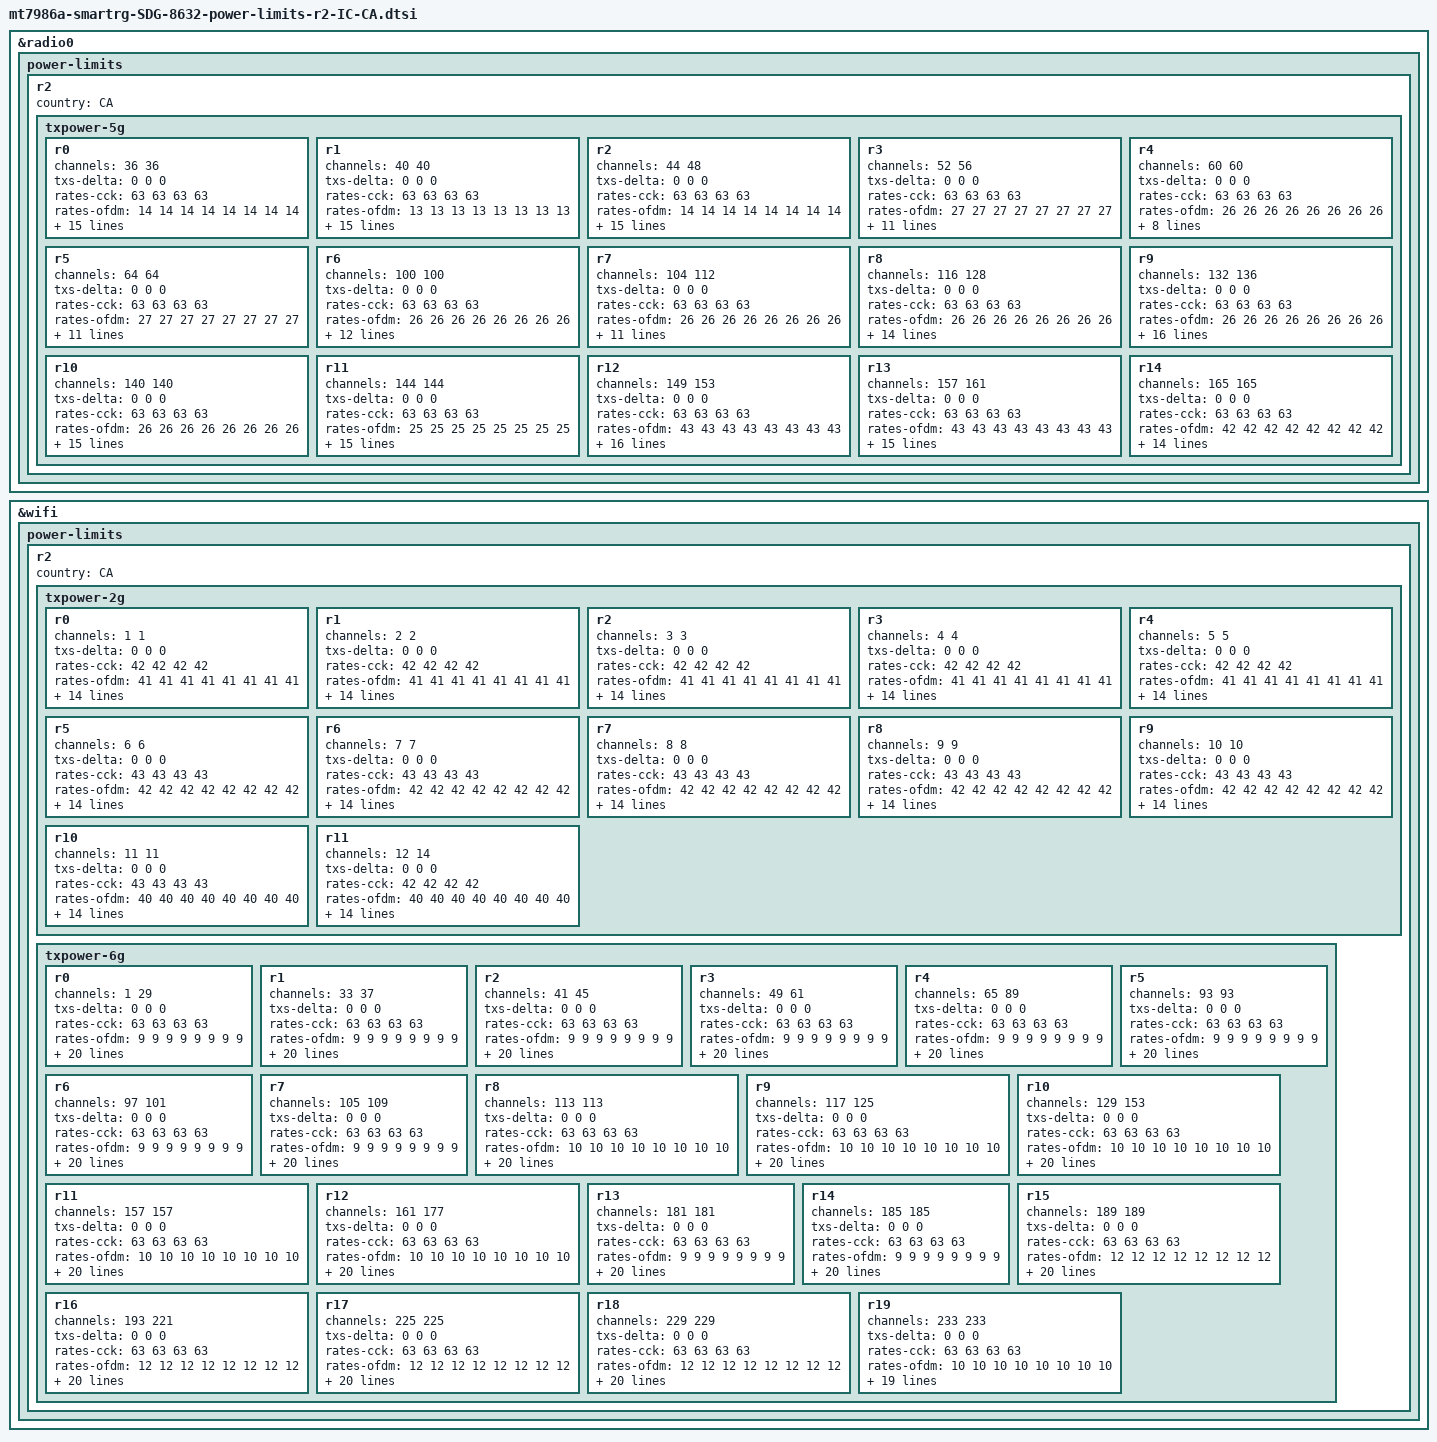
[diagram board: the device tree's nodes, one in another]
// SPDX-License-Identifier: (GPL-2.0 OR MIT)
/*
 * Copyright (C) 2022 SmartRG Inc.
 * Author: Chad Monroe <chad.monroe@smartrg.com>
 */

&radio0 {
	power-limits {
		r2 {
			country = "CA";

			txpower-5g {
				r0 {
					channels = <36 36>;
					txs-delta = <0 0 0>;
					rates-cck = /bits/ 8 <63 63 63 63>;
					rates-ofdm = /bits/ 8 <14 14 14 14 14 14 14 14>;
					rates-mcs =
					/bits/ 8 <1 15 15 15 15 15 15 15 15 15 15>,
					/bits/ 8 <1 19 19 19 19 19 19 19 19 19 19>,
					/bits/ 8 <2 24 24 24 24 24 24 24 24 24 24>;
					rates-ru =
					/bits/ 8 <4 15 15 15 15 15 15 15 15 15 15 15 15>,
					/bits/ 8 <1 19 19 19 19 19 19 19 19 19 19 19 19>,
					/bits/ 8 <2 24 24 24 24 24 24 24 24 24 24 24 24>;
					paths-ofdm = /bits/ 8 <14 14 14 14>;
					paths-ofdm-bf = /bits/ 8 <0 14 14 14>;
					paths-ru =
					/bits/ 8 <4 15 15 15 15 15 15 15 15 15 15>,
					/bits/ 8 <1 19 19 19 19 19 19 19 19 19 19>,
					/bits/ 8 <2 24 24 24 24 24 24 24 24 24 24>;
					paths-ru-bf =
					/bits/ 8 <3 14 14 14 14 14 14 14 14 14 14>,
					/bits/ 8 <1 0 14 14 14 14 14 14 14 14 14>,
					/bits/ 8 <3 0 15 15 15 15 15 15 15 15 15>;
				};
				r1 {
					channels = <40 40>;
					txs-delta = <0 0 0>;
					rates-cck = /bits/ 8 <63 63 63 63>;
					rates-ofdm = /bits/ 8 <13 13 13 13 13 13 13 13>;
					rates-mcs =
					/bits/ 8 <1 15 15 15 15 15 15 15 15 15 15>,
					/bits/ 8 <1 19 19 19 19 19 19 19 19 19 19>,
					/bits/ 8 <2 24 24 24 24 24 24 24 24 24 24>;
					rates-ru =
					/bits/ 8 <4 15 15 15 15 15 15 15 15 15 15 15 15>,
					/bits/ 8 <1 19 19 19 19 19 19 19 19 19 19 19 19>,
					/bits/ 8 <2 24 24 24 24 24 24 24 24 24 24 24 24>;
					paths-ofdm = /bits/ 8 <13 13 13 13>;
					paths-ofdm-bf = /bits/ 8 <0 13 13 13>;
					paths-ru =
					/bits/ 8 <4 15 15 15 15 15 15 15 15 15 15>,
					/bits/ 8 <1 19 19 19 19 19 19 19 19 19 19>,
					/bits/ 8 <2 24 24 24 24 24 24 24 24 24 24>;
					paths-ru-bf =
					/bits/ 8 <3 14 14 14 14 14 14 14 14 14 14>,
					/bits/ 8 <1 0 14 14 14 14 14 14 14 14 14>,
					/bits/ 8 <3 0 15 15 15 15 15 15 15 15 15>;
				};
				r2 {
					channels = <44 48>;
					txs-delta = <0 0 0>;
					rates-cck = /bits/ 8 <63 63 63 63>;
					rates-ofdm = /bits/ 8 <14 14 14 14 14 14 14 14>;
					rates-mcs =
					/bits/ 8 <1 15 15 15 15 15 15 15 15 15 15>,
					/bits/ 8 <1 19 19 19 19 19 19 19 19 19 19>,
					/bits/ 8 <2 24 24 24 24 24 24 24 24 24 24>;
					rates-ru =
					/bits/ 8 <4 15 15 15 15 15 15 15 15 15 15 15 15>,
					/bits/ 8 <1 19 19 19 19 19 19 19 19 19 19 19 19>,
					/bits/ 8 <2 24 24 24 24 24 24 24 24 24 24 24 24>;
					paths-ofdm = /bits/ 8 <14 14 14 14>;
					paths-ofdm-bf = /bits/ 8 <0 14 14 14>;
					paths-ru =
					/bits/ 8 <4 15 15 15 15 15 15 15 15 15 15>,
					/bits/ 8 <1 19 19 19 19 19 19 19 19 19 19>,
					/bits/ 8 <2 24 24 24 24 24 24 24 24 24 24>;
					paths-ru-bf =
					/bits/ 8 <3 14 14 14 14 14 14 14 14 14 14>,
					/bits/ 8 <1 0 14 14 14 14 14 14 14 14 14>,
					/bits/ 8 <3 0 15 15 15 15 15 15 15 15 15>;
				};
				r3 {
					channels = <52 56>;
					txs-delta = <0 0 0>;
					rates-cck = /bits/ 8 <63 63 63 63>;
					rates-ofdm = /bits/ 8 <27 27 27 27 27 27 27 27>;
					rates-mcs =
					/bits/ 8 <1 27 27 27 27 27 27 27 27 27 27>,
					/bits/ 8 <3 26 26 26 26 26 26 26 26 26 26>;
					rates-ru =
					/bits/ 8 <4 27 27 27 27 27 27 27 27 27 27 27 27>,
					/bits/ 8 <3 26 26 26 26 26 26 26 26 26 26 26 26>;
					paths-ofdm = /bits/ 8 <27 27 27 27>;
					paths-ofdm-bf = /bits/ 8 <0 27 27 27>;
					paths-ru =
					/bits/ 8 <4 27 27 27 27 27 27 27 27 27 27>,
					/bits/ 8 <3 26 26 26 26 26 26 26 26 26 26>;
					paths-ru-bf =
					/bits/ 8 <3 15 15 15 15 15 15 15 15 15 15>,
					/bits/ 8 <4 0 15 15 15 15 15 15 15 15 15>;
				};
				r4 {
					channels = <60 60>;
					txs-delta = <0 0 0>;
					rates-cck = /bits/ 8 <63 63 63 63>;
					rates-ofdm = /bits/ 8 <26 26 26 26 26 26 26 26>;
					rates-mcs =
					/bits/ 8 <4 26 26 26 26 26 26 26 26 26 26>;
					rates-ru =
					/bits/ 8 <7 26 26 26 26 26 26 26 26 26 26 26 26>;
					paths-ofdm = /bits/ 8 <26 26 26 26>;
					paths-ofdm-bf = /bits/ 8 <0 26 26 26>;
					paths-ru =
					/bits/ 8 <7 26 26 26 26 26 26 26 26 26 26>;
					paths-ru-bf =
					/bits/ 8 <3 15 15 15 15 15 15 15 15 15 15>,
					/bits/ 8 <4 0 15 15 15 15 15 15 15 15 15>;
				};
				r5 {
					channels = <64 64>;
					txs-delta = <0 0 0>;
					rates-cck = /bits/ 8 <63 63 63 63>;
					rates-ofdm = /bits/ 8 <27 27 27 27 27 27 27 27>;
					rates-mcs =
					/bits/ 8 <1 27 27 27 27 27 27 27 27 27 27>,
					/bits/ 8 <3 26 26 26 26 26 26 26 26 26 26>;
					rates-ru =
					/bits/ 8 <4 27 27 27 27 27 27 27 27 27 27 27 27>,
					/bits/ 8 <3 26 26 26 26 26 26 26 26 26 26 26 26>;
					paths-ofdm = /bits/ 8 <27 27 27 27>;
					paths-ofdm-bf = /bits/ 8 <0 27 27 27>;
					paths-ru =
					/bits/ 8 <4 27 27 27 27 27 27 27 27 27 27>,
					/bits/ 8 <3 26 26 26 26 26 26 26 26 26 26>;
					paths-ru-bf =
					/bits/ 8 <3 15 15 15 15 15 15 15 15 15 15>,
					/bits/ 8 <4 0 15 15 15 15 15 15 15 15 15>;
				};
				r6 {
					channels = <100 100>;
					txs-delta = <0 0 0>;
					rates-cck = /bits/ 8 <63 63 63 63>;
					rates-ofdm = /bits/ 8 <26 26 26 26 26 26 26 26>;
					rates-mcs =
					/bits/ 8 <1 28 28 28 28 28 28 28 28 28 28>,
					/bits/ 8 <3 31 31 31 31 31 31 31 31 31 31>;
					rates-ru =
					/bits/ 8 <4 28 28 28 28 28 28 28 28 28 28 28 28>,
					/bits/ 8 <3 31 31 31 31 31 31 31 31 31 31 31 31>;
					paths-ofdm = /bits/ 8 <26 26 26 26>;
					paths-ofdm-bf = /bits/ 8 <0 26 26 26>;
					paths-ru =
					/bits/ 8 <4 28 28 28 28 28 28 28 28 28 28>,
					/bits/ 8 <3 31 31 31 31 31 31 31 31 31 31>;
					paths-ru-bf =
					/bits/ 8 <3 27 27 27 27 27 27 27 27 27 27>,
					/bits/ 8 <1 0 27 27 27 27 27 27 27 27 27>,
					/bits/ 8 <3 0 28 28 28 28 28 28 28 28 28>;
				};
				r7 {
					channels = <104 112>;
					txs-delta = <0 0 0>;
					rates-cck = /bits/ 8 <63 63 63 63>;
					rates-ofdm = /bits/ 8 <26 26 26 26 26 26 26 26>;
					rates-mcs =
					/bits/ 8 <1 28 28 28 28 28 28 28 28 28 28>,
					/bits/ 8 <3 31 31 31 31 31 31 31 31 31 31>;
					rates-ru =
					/bits/ 8 <4 28 28 28 28 28 28 28 28 28 28 28 28>,
					/bits/ 8 <3 31 31 31 31 31 31 31 31 31 31 31 31>;
					paths-ofdm = /bits/ 8 <26 26 26 26>;
					paths-ofdm-bf = /bits/ 8 <0 26 26 26>;
					paths-ru =
					/bits/ 8 <4 28 28 28 28 28 28 28 28 28 28>,
					/bits/ 8 <3 31 31 31 31 31 31 31 31 31 31>;
					paths-ru-bf =
					/bits/ 8 <3 28 28 28 28 28 28 28 28 28 28>,
					/bits/ 8 <4 0 28 28 28 28 28 28 28 28 28>;
				};
				r8 {
					channels = <116 128>;
					txs-delta = <0 0 0>;
					rates-cck = /bits/ 8 <63 63 63 63>;
					rates-ofdm = /bits/ 8 <26 26 26 26 26 26 26 26>;
					rates-mcs =
					/bits/ 8 <1 28 28 28 28 28 28 28 28 28 28>,
					/bits/ 8 <1 31 31 31 31 31 31 31 31 31 31>,
					/bits/ 8 <2 35 35 35 35 35 35 35 35 35 35>;
					rates-ru =
					/bits/ 8 <4 28 28 28 28 28 28 28 28 28 28 28 28>,
					/bits/ 8 <1 31 31 31 31 31 31 31 31 31 31 31 31>,
					/bits/ 8 <2 35 35 35 35 35 35 35 35 35 35 35 35>;
					paths-ofdm = /bits/ 8 <26 26 26 26>;
					paths-ofdm-bf = /bits/ 8 <0 26 26 26>;
					paths-ru =
					/bits/ 8 <4 28 28 28 28 28 28 28 28 28 28>,
					/bits/ 8 <1 31 31 31 31 31 31 31 31 31 31>,
					/bits/ 8 <2 35 35 35 35 35 35 35 35 35 35>;
					paths-ru-bf =
					/bits/ 8 <3 28 28 28 28 28 28 28 28 28 28>,
					/bits/ 8 <4 0 28 28 28 28 28 28 28 28 28>;
				};
				r9 {
					channels = <132 136>;
					txs-delta = <0 0 0>;
					rates-cck = /bits/ 8 <63 63 63 63>;
					rates-ofdm = /bits/ 8 <26 26 26 26 26 26 26 26>;
					rates-mcs =
					/bits/ 8 <1 28 28 28 28 28 28 28 28 28 28>,
					/bits/ 8 <1 31 31 31 31 31 31 31 31 31 31>,
					/bits/ 8 <2 35 35 35 35 35 35 35 35 35 35>;
					rates-ru =
					/bits/ 8 <4 28 28 28 28 28 28 28 28 28 28 28 28>,
					/bits/ 8 <1 31 31 31 31 31 31 31 31 31 31 31 31>,
					/bits/ 8 <2 35 35 35 35 35 35 35 35 35 35 35 35>;
					paths-ofdm = /bits/ 8 <26 26 26 26>;
					paths-ofdm-bf = /bits/ 8 <0 26 26 26>;
					paths-ru =
					/bits/ 8 <4 28 28 28 28 28 28 28 28 28 28>,
					/bits/ 8 <1 31 31 31 31 31 31 31 31 31 31>,
					/bits/ 8 <2 35 35 35 35 35 35 35 35 35 35>;
					paths-ru-bf =
					/bits/ 8 <3 28 28 28 28 28 28 28 28 28 28>,
					/bits/ 8 <1 0 28 28 28 28 28 28 28 28 28>,
					/bits/ 8 <1 0 29 29 29 29 29 29 29 29 29>,
					/bits/ 8 <2 0 28 28 28 28 28 28 28 28 28>;
				};
				r10 {
					channels = <140 140>;
					txs-delta = <0 0 0>;
					rates-cck = /bits/ 8 <63 63 63 63>;
					rates-ofdm = /bits/ 8 <26 26 26 26 26 26 26 26>;
					rates-mcs =
					/bits/ 8 <1 27 27 27 27 27 27 27 27 27 27>,
					/bits/ 8 <1 32 32 32 32 32 32 32 32 32 32>,
					/bits/ 8 <2 35 35 35 35 35 35 35 35 35 35>;
					rates-ru =
					/bits/ 8 <4 27 27 27 27 27 27 27 27 27 27 27 27>,
					/bits/ 8 <1 32 32 32 32 32 32 32 32 32 32 32 32>,
					/bits/ 8 <2 35 35 35 35 35 35 35 35 35 35 35 35>;
					paths-ofdm = /bits/ 8 <26 26 26 26>;
					paths-ofdm-bf = /bits/ 8 <0 26 26 26>;
					paths-ru =
					/bits/ 8 <4 27 27 27 27 27 27 27 27 27 27>,
					/bits/ 8 <1 32 32 32 32 32 32 32 32 32 32>,
					/bits/ 8 <2 35 35 35 35 35 35 35 35 35 35>;
					paths-ru-bf =
					/bits/ 8 <3 27 27 27 27 27 27 27 27 27 27>,
					/bits/ 8 <1 0 27 27 27 27 27 27 27 27 27>,
					/bits/ 8 <3 0 28 28 28 28 28 28 28 28 28>;
				};
				r11 {
					channels = <144 144>;
					txs-delta = <0 0 0>;
					rates-cck = /bits/ 8 <63 63 63 63>;
					rates-ofdm = /bits/ 8 <25 25 25 25 25 25 25 25>;
					rates-mcs =
					/bits/ 8 <1 26 26 26 26 26 26 26 26 26 26>,
					/bits/ 8 <1 32 32 32 32 32 32 32 32 32 32>,
					/bits/ 8 <2 35 35 35 35 35 35 35 35 35 35>;
					rates-ru =
					/bits/ 8 <4 26 26 26 26 26 26 26 26 26 26 26 26>,
					/bits/ 8 <1 32 32 32 32 32 32 32 32 32 32 32 32>,
					/bits/ 8 <2 35 35 35 35 35 35 35 35 35 35 35 35>;
					paths-ofdm = /bits/ 8 <25 25 25 25>;
					paths-ofdm-bf = /bits/ 8 <0 25 25 25>;
					paths-ru =
					/bits/ 8 <4 26 26 26 26 26 26 26 26 26 26>,
					/bits/ 8 <1 32 32 32 32 32 32 32 32 32 32>,
					/bits/ 8 <2 35 35 35 35 35 35 35 35 35 35>;
					paths-ru-bf =
					/bits/ 8 <3 26 26 26 26 26 26 26 26 26 26>,
					/bits/ 8 <1 0 26 26 26 26 26 26 26 26 26>,
					/bits/ 8 <3 0 28 28 28 28 28 28 28 28 28>;
				};
				r12 {
					channels = <149 153>;
					txs-delta = <0 0 0>;
					rates-cck = /bits/ 8 <63 63 63 63>;
					rates-ofdm = /bits/ 8 <43 43 43 43 43 43 43 43>;
					rates-mcs =
					/bits/ 8 <1 43 43 43 43 43 43 43 43 43 43>,
					/bits/ 8 <1 41 41 41 41 41 41 41 41 41 41>,
					/bits/ 8 <2 34 34 34 34 34 34 34 34 34 34>;
					rates-ru =
					/bits/ 8 <4 43 43 43 43 43 43 43 43 43 43 43 43>,
					/bits/ 8 <1 41 41 41 41 41 41 41 41 41 41 41 41>,
					/bits/ 8 <2 34 34 34 34 34 34 34 34 34 34 34 34>;
					paths-ofdm = /bits/ 8 <43 43 43 43>;
					paths-ofdm-bf = /bits/ 8 <0 43 43 43>;
					paths-ru =
					/bits/ 8 <4 43 43 43 43 43 43 43 43 43 43>,
					/bits/ 8 <1 41 41 41 41 41 41 41 41 41 41>,
					/bits/ 8 <2 34 34 34 34 34 34 34 34 34 34>;
					paths-ru-bf =
					/bits/ 8 <3 40 40 40 40 40 40 40 40 40 40>,
					/bits/ 8 <1 0 40 40 40 40 40 40 40 40 40>,
					/bits/ 8 <1 0 38 38 38 38 38 38 38 38 38>,
					/bits/ 8 <2 0 33 33 33 33 33 33 33 33 33>;
				};
				r13 {
					channels = <157 161>;
					txs-delta = <0 0 0>;
					rates-cck = /bits/ 8 <63 63 63 63>;
					rates-ofdm = /bits/ 8 <43 43 43 43 43 43 43 43>;
					rates-mcs =
					/bits/ 8 <1 42 42 42 42 42 42 42 42 42 42>,
					/bits/ 8 <1 44 44 44 44 44 44 44 44 44 44>,
					/bits/ 8 <2 34 34 34 34 34 34 34 34 34 34>;
					rates-ru =
					/bits/ 8 <4 42 42 42 42 42 42 42 42 42 42 42 42>,
					/bits/ 8 <1 44 44 44 44 44 44 44 44 44 44 44 44>,
					/bits/ 8 <2 34 34 34 34 34 34 34 34 34 34 34 34>;
					paths-ofdm = /bits/ 8 <43 43 43 43>;
					paths-ofdm-bf = /bits/ 8 <0 43 43 43>;
					paths-ru =
					/bits/ 8 <4 42 42 42 42 42 42 42 42 42 42>,
					/bits/ 8 <1 44 44 44 44 44 44 44 44 44 44>,
					/bits/ 8 <2 34 34 34 34 34 34 34 34 34 34>;
					paths-ru-bf =
					/bits/ 8 <3 40 40 40 40 40 40 40 40 40 40>,
					/bits/ 8 <2 0 40 40 40 40 40 40 40 40 40>,
					/bits/ 8 <2 0 33 33 33 33 33 33 33 33 33>;
				};
				r14 {
					channels = <165 165>;
					txs-delta = <0 0 0>;
					rates-cck = /bits/ 8 <63 63 63 63>;
					rates-ofdm = /bits/ 8 <42 42 42 42 42 42 42 42>;
					rates-mcs =
					/bits/ 8 <1 42 42 42 42 42 42 42 42 42 42>,
					/bits/ 8 <3 31 31 31 31 31 31 31 31 31 31>;
					rates-ru =
					/bits/ 8 <4 42 42 42 42 42 42 42 42 42 42 42 42>,
					/bits/ 8 <3 31 31 31 31 31 31 31 31 31 31 31 31>;
					paths-ofdm = /bits/ 8 <42 42 42 42>;
					paths-ofdm-bf = /bits/ 8 <0 42 42 42>;
					paths-ru =
					/bits/ 8 <4 42 42 42 42 42 42 42 42 42 42>,
					/bits/ 8 <1 46 46 46 46 46 46 46 46 46 46>,
					/bits/ 8 <2 31 31 31 31 31 31 31 31 31 31>;
					paths-ru-bf =
					/bits/ 8 <3 40 40 40 40 40 40 40 40 40 40>,
					/bits/ 8 <1 0 40 40 40 40 40 40 40 40 40>,
					/bits/ 8 <1 0 39 39 39 39 39 39 39 39 39>,
					/bits/ 8 <2 0 26 26 26 26 26 26 26 26 26>;
				};
			};
		};
	};
};

&wifi {
	power-limits {
		r2 {
			country = "CA";

			txpower-2g {
				r0 {
					channels = <1 1>;
					txs-delta = <0 0 0>;
					rates-cck = /bits/ 8 <42 42 42 42>;
					rates-ofdm = /bits/ 8 <41 41 41 41 41 41 41 41>;
					rates-mcs =
					/bits/ 8 <1 37 37 37 37 37 37 37 37 37 37>,
					/bits/ 8 <3 30 30 30 30 30 30 30 30 30 30>;
					rates-ru =
					/bits/ 8 <4 37 37 37 37 37 37 37 37 37 37 37 37>,
					/bits/ 8 <3 30 30 30 30 30 30 30 30 30 30 30 30>;
					paths-cck = /bits/ 8 <42 42 42 42>;
					paths-ofdm = /bits/ 8 <41 41 41 41>;
					paths-ofdm-bf = /bits/ 8 <0 27 27 27>;
					paths-ru =
					/bits/ 8 <4 37 37 37 37 37 37 37 37 37 37>,
					/bits/ 8 <1 30 30 30 30 30 30 30 30 30 30>,
					/bits/ 8 <2 37 37 37 37 37 37 37 37 37 37>;
					paths-ru-bf =
					/bits/ 8 <3 27 27 27 27 27 27 27 27 27 27>,
					/bits/ 8 <1 0 27 27 27 27 27 27 27 27 27>,
					/bits/ 8 <3 0 26 26 26 26 26 26 26 26 26>;
				};
				r1 {
					channels = <2 2>;
					txs-delta = <0 0 0>;
					rates-cck = /bits/ 8 <42 42 42 42>;
					rates-ofdm = /bits/ 8 <41 41 41 41 41 41 41 41>;
					rates-mcs =
					/bits/ 8 <1 38 38 38 38 38 38 38 38 38 38>,
					/bits/ 8 <3 30 30 30 30 30 30 30 30 30 30>;
					rates-ru =
					/bits/ 8 <4 38 38 38 38 38 38 38 38 38 38 38 38>,
					/bits/ 8 <3 30 30 30 30 30 30 30 30 30 30 30 30>;
					paths-cck = /bits/ 8 <42 42 42 42>;
					paths-ofdm = /bits/ 8 <41 41 41 41>;
					paths-ofdm-bf = /bits/ 8 <0 29 29 29>;
					paths-ru =
					/bits/ 8 <4 38 38 38 38 38 38 38 38 38 38>,
					/bits/ 8 <1 30 30 30 30 30 30 30 30 30 30>,
					/bits/ 8 <2 38 38 38 38 38 38 38 38 38 38>;
					paths-ru-bf =
					/bits/ 8 <3 29 29 29 29 29 29 29 29 29 29>,
					/bits/ 8 <1 0 29 29 29 29 29 29 29 29 29>,
					/bits/ 8 <3 0 26 26 26 26 26 26 26 26 26>;
				};
				r2 {
					channels = <3 3>;
					txs-delta = <0 0 0>;
					rates-cck = /bits/ 8 <42 42 42 42>;
					rates-ofdm = /bits/ 8 <41 41 41 41 41 41 41 41>;
					rates-mcs =
					/bits/ 8 <1 39 39 39 39 39 39 39 39 39 39>,
					/bits/ 8 <3 30 30 30 30 30 30 30 30 30 30>;
					rates-ru =
					/bits/ 8 <4 39 39 39 39 39 39 39 39 39 39 39 39>,
					/bits/ 8 <3 30 30 30 30 30 30 30 30 30 30 30 30>;
					paths-cck = /bits/ 8 <42 42 42 42>;
					paths-ofdm = /bits/ 8 <41 41 41 41>;
					paths-ofdm-bf = /bits/ 8 <0 35 35 35>;
					paths-ru =
					/bits/ 8 <4 39 39 39 39 39 39 39 39 39 39>,
					/bits/ 8 <1 30 30 30 30 30 30 30 30 30 30>,
					/bits/ 8 <2 39 39 39 39 39 39 39 39 39 39>;
					paths-ru-bf =
					/bits/ 8 <3 35 35 35 35 35 35 35 35 35 35>,
					/bits/ 8 <1 0 35 35 35 35 35 35 35 35 35>,
					/bits/ 8 <3 0 26 26 26 26 26 26 26 26 26>;
				};
				r3 {
					channels = <4 4>;
					txs-delta = <0 0 0>;
					rates-cck = /bits/ 8 <42 42 42 42>;
					rates-ofdm = /bits/ 8 <41 41 41 41 41 41 41 41>;
					rates-mcs =
					/bits/ 8 <1 40 40 40 40 40 40 40 40 40 40>,
					/bits/ 8 <3 32 32 32 32 32 32 32 32 32 32>;
					rates-ru =
					/bits/ 8 <4 40 40 40 40 40 40 40 40 40 40 40 40>,
					/bits/ 8 <3 32 32 32 32 32 32 32 32 32 32 32 32>;
					paths-cck = /bits/ 8 <42 42 42 42>;
					paths-ofdm = /bits/ 8 <41 41 41 41>;
					paths-ofdm-bf = /bits/ 8 <0 37 37 37>;
					paths-ru =
					/bits/ 8 <4 40 40 40 40 40 40 40 40 40 40>,
					/bits/ 8 <1 32 32 32 32 32 32 32 32 32 32>,
					/bits/ 8 <2 40 40 40 40 40 40 40 40 40 40>;
					paths-ru-bf =
					/bits/ 8 <3 37 37 37 37 37 37 37 37 37 37>,
					/bits/ 8 <1 0 37 37 37 37 37 37 37 37 37>,
					/bits/ 8 <3 0 33 33 33 33 33 33 33 33 33>;
				};
				r4 {
					channels = <5 5>;
					txs-delta = <0 0 0>;
					rates-cck = /bits/ 8 <42 42 42 42>;
					rates-ofdm = /bits/ 8 <41 41 41 41 41 41 41 41>;
					rates-mcs =
					/bits/ 8 <1 41 41 41 41 41 41 41 41 41 41>,
					/bits/ 8 <3 34 34 34 34 34 34 34 34 34 34>;
					rates-ru =
					/bits/ 8 <4 41 41 41 41 41 41 41 41 41 41 41 41>,
					/bits/ 8 <3 34 34 34 34 34 34 34 34 34 34 34 34>;
					paths-cck = /bits/ 8 <42 42 42 42>;
					paths-ofdm = /bits/ 8 <41 41 41 41>;
					paths-ofdm-bf = /bits/ 8 <0 39 39 39>;
					paths-ru =
					/bits/ 8 <4 41 41 41 41 41 41 41 41 41 41>,
					/bits/ 8 <1 34 34 34 34 34 34 34 34 34 34>,
					/bits/ 8 <2 41 41 41 41 41 41 41 41 41 41>;
					paths-ru-bf =
					/bits/ 8 <3 39 39 39 39 39 39 39 39 39 39>,
					/bits/ 8 <1 0 39 39 39 39 39 39 39 39 39>,
					/bits/ 8 <3 0 35 35 35 35 35 35 35 35 35>;
				};
				r5 {
					channels = <6 6>;
					txs-delta = <0 0 0>;
					rates-cck = /bits/ 8 <43 43 43 43>;
					rates-ofdm = /bits/ 8 <42 42 42 42 42 42 42 42>;
					rates-mcs =
					/bits/ 8 <1 42 42 42 42 42 42 42 42 42 42>,
					/bits/ 8 <3 37 37 37 37 37 37 37 37 37 37>;
					rates-ru =
					/bits/ 8 <4 42 42 42 42 42 42 42 42 42 42 42 42>,
					/bits/ 8 <3 37 37 37 37 37 37 37 37 37 37 37 37>;
					paths-cck = /bits/ 8 <43 43 43 43>;
					paths-ofdm = /bits/ 8 <42 42 42 42>;
					paths-ofdm-bf = /bits/ 8 <0 40 40 40>;
					paths-ru =
					/bits/ 8 <4 42 42 42 42 42 42 42 42 42 42>,
					/bits/ 8 <1 37 37 37 37 37 37 37 37 37 37>,
					/bits/ 8 <2 42 42 42 42 42 42 42 42 42 42>;
					paths-ru-bf =
					/bits/ 8 <3 40 40 40 40 40 40 40 40 40 40>,
					/bits/ 8 <1 0 40 40 40 40 40 40 40 40 40>,
					/bits/ 8 <3 0 37 37 37 37 37 37 37 37 37>;
				};
				r6 {
					channels = <7 7>;
					txs-delta = <0 0 0>;
					rates-cck = /bits/ 8 <43 43 43 43>;
					rates-ofdm = /bits/ 8 <42 42 42 42 42 42 42 42>;
					rates-mcs =
					/bits/ 8 <1 41 41 41 41 41 41 41 41 41 41>,
					/bits/ 8 <3 33 33 33 33 33 33 33 33 33 33>;
					rates-ru =
					/bits/ 8 <4 41 41 41 41 41 41 41 41 41 41 41 41>,
					/bits/ 8 <3 33 33 33 33 33 33 33 33 33 33 33 33>;
					paths-cck = /bits/ 8 <43 43 43 43>;
					paths-ofdm = /bits/ 8 <42 42 42 42>;
					paths-ofdm-bf = /bits/ 8 <0 39 39 39>;
					paths-ru =
					/bits/ 8 <4 41 41 41 41 41 41 41 41 41 41>,
					/bits/ 8 <1 33 33 33 33 33 33 33 33 33 33>,
					/bits/ 8 <2 41 41 41 41 41 41 41 41 41 41>;
					paths-ru-bf =
					/bits/ 8 <3 39 39 39 39 39 39 39 39 39 39>,
					/bits/ 8 <1 0 39 39 39 39 39 39 39 39 39>,
					/bits/ 8 <3 0 35 35 35 35 35 35 35 35 35>;
				};
				r7 {
					channels = <8 8>;
					txs-delta = <0 0 0>;
					rates-cck = /bits/ 8 <43 43 43 43>;
					rates-ofdm = /bits/ 8 <42 42 42 42 42 42 42 42>;
					rates-mcs =
					/bits/ 8 <1 40 40 40 40 40 40 40 40 40 40>,
					/bits/ 8 <3 31 31 31 31 31 31 31 31 31 31>;
					rates-ru =
					/bits/ 8 <4 40 40 40 40 40 40 40 40 40 40 40 40>,
					/bits/ 8 <3 31 31 31 31 31 31 31 31 31 31 31 31>;
					paths-cck = /bits/ 8 <43 43 43 43>;
					paths-ofdm = /bits/ 8 <42 42 42 42>;
					paths-ofdm-bf = /bits/ 8 <0 37 37 37>;
					paths-ru =
					/bits/ 8 <4 40 40 40 40 40 40 40 40 40 40>,
					/bits/ 8 <1 31 31 31 31 31 31 31 31 31 31>,
					/bits/ 8 <2 40 40 40 40 40 40 40 40 40 40>;
					paths-ru-bf =
					/bits/ 8 <3 37 37 37 37 37 37 37 37 37 37>,
					/bits/ 8 <1 0 37 37 37 37 37 37 37 37 37>,
					/bits/ 8 <3 0 33 33 33 33 33 33 33 33 33>;
				};
				r8 {
					channels = <9 9>;
					txs-delta = <0 0 0>;
					rates-cck = /bits/ 8 <43 43 43 43>;
					rates-ofdm = /bits/ 8 <42 42 42 42 42 42 42 42>;
					rates-mcs =
					/bits/ 8 <1 38 38 38 38 38 38 38 38 38 38>,
					/bits/ 8 <3 29 29 29 29 29 29 29 29 29 29>;
					rates-ru =
					/bits/ 8 <4 38 38 38 38 38 38 38 38 38 38 38 38>,
					/bits/ 8 <3 29 29 29 29 29 29 29 29 29 29 29 29>;
					paths-cck = /bits/ 8 <43 43 43 43>;
					paths-ofdm = /bits/ 8 <42 42 42 42>;
					paths-ofdm-bf = /bits/ 8 <0 35 35 35>;
					paths-ru =
					/bits/ 8 <4 38 38 38 38 38 38 38 38 38 38>,
					/bits/ 8 <1 29 29 29 29 29 29 29 29 29 29>,
					/bits/ 8 <2 38 38 38 38 38 38 38 38 38 38>;
					paths-ru-bf =
					/bits/ 8 <3 35 35 35 35 35 35 35 35 35 35>,
					/bits/ 8 <1 0 35 35 35 35 35 35 35 35 35>,
					/bits/ 8 <3 0 23 23 23 23 23 23 23 23 23>;
				};
				r9 {
					channels = <10 10>;
					txs-delta = <0 0 0>;
					rates-cck = /bits/ 8 <43 43 43 43>;
					rates-ofdm = /bits/ 8 <42 42 42 42 42 42 42 42>;
					rates-mcs =
					/bits/ 8 <1 36 36 36 36 36 36 36 36 36 36>,
					/bits/ 8 <3 27 27 27 27 27 27 27 27 27 27>;
					rates-ru =
					/bits/ 8 <4 36 36 36 36 36 36 36 36 36 36 36 36>,
					/bits/ 8 <3 27 27 27 27 27 27 27 27 27 27 27 27>;
					paths-cck = /bits/ 8 <43 43 43 43>;
					paths-ofdm = /bits/ 8 <42 42 42 42>;
					paths-ofdm-bf = /bits/ 8 <0 27 27 27>;
					paths-ru =
					/bits/ 8 <4 36 36 36 36 36 36 36 36 36 36>,
					/bits/ 8 <1 27 27 27 27 27 27 27 27 27 27>,
					/bits/ 8 <2 36 36 36 36 36 36 36 36 36 36>;
					paths-ru-bf =
					/bits/ 8 <3 27 27 27 27 27 27 27 27 27 27>,
					/bits/ 8 <1 0 27 27 27 27 27 27 27 27 27>,
					/bits/ 8 <3 0 23 23 23 23 23 23 23 23 23>;
				};
				r10 {
					channels = <11 11>;
					txs-delta = <0 0 0>;
					rates-cck = /bits/ 8 <43 43 43 43>;
					rates-ofdm = /bits/ 8 <40 40 40 40 40 40 40 40>;
					rates-mcs =
					/bits/ 8 <1 34 34 34 34 34 34 34 34 34 34>,
					/bits/ 8 <3 25 25 25 25 25 25 25 25 25 25>;
					rates-ru =
					/bits/ 8 <4 34 34 34 34 34 34 34 34 34 34 34 34>,
					/bits/ 8 <3 25 25 25 25 25 25 25 25 25 25 25 25>;
					paths-cck = /bits/ 8 <43 43 43 43>;
					paths-ofdm = /bits/ 8 <40 40 40 40>;
					paths-ofdm-bf = /bits/ 8 <0 25 25 25>;
					paths-ru =
					/bits/ 8 <4 34 34 34 34 34 34 34 34 34 34>,
					/bits/ 8 <1 25 25 25 25 25 25 25 25 25 25>,
					/bits/ 8 <2 34 34 34 34 34 34 34 34 34 34>;
					paths-ru-bf =
					/bits/ 8 <3 25 25 25 25 25 25 25 25 25 25>,
					/bits/ 8 <1 0 25 25 25 25 25 25 25 25 25>,
					/bits/ 8 <3 0 23 23 23 23 23 23 23 23 23>;
				};
				r11 {
					channels = <12 14>;
					txs-delta = <0 0 0>;
					rates-cck = /bits/ 8 <42 42 42 42>;
					rates-ofdm = /bits/ 8 <40 40 40 40 40 40 40 40>;
					rates-mcs =
					/bits/ 8 <1 34 34 34 34 34 34 34 34 34 34>,
					/bits/ 8 <3 25 25 25 25 25 25 25 25 25 25>;
					rates-ru =
					/bits/ 8 <4 34 34 34 34 34 34 34 34 34 34 34 34>,
					/bits/ 8 <3 25 25 25 25 25 25 25 25 25 25 25 25>;
					paths-cck = /bits/ 8 <42 42 42 42>;
					paths-ofdm = /bits/ 8 <40 40 40 40>;
					paths-ofdm-bf = /bits/ 8 <0 25 25 25>;
					paths-ru =
					/bits/ 8 <4 34 34 34 34 34 34 34 34 34 34>,
					/bits/ 8 <1 25 25 25 25 25 25 25 25 25 25>,
					/bits/ 8 <2 34 34 34 34 34 34 34 34 34 34>;
					paths-ru-bf =
					/bits/ 8 <3 25 25 25 25 25 25 25 25 25 25>,
					/bits/ 8 <1 0 25 25 25 25 25 25 25 25 25>,
					/bits/ 8 <3 0 23 23 23 23 23 23 23 23 23>;
				};
			};

			txpower-6g {
				r0 {
					channels = <1 29>;
					txs-delta = <0 0 0>;
					rates-cck = /bits/ 8 <63 63 63 63>;
					rates-ofdm = /bits/ 8 <9 9 9 9 9 9 9 9>;
					rates-mcs =
					/bits/ 8 <1 11 11 11 11 11 11 11 11 11 11>,
					/bits/ 8 <1 17 17 17 17 17 17 17 17 17 17>,
					/bits/ 8 <1 22 22 22 22 22 22 22 22 22 22>,
					/bits/ 8 <1 27 27 27 27 27 27 27 27 27 27>;
					rates-ru =
					/bits/ 8 <4 11 11 11 11 11 11 11 11 11 11 11 11>,
					/bits/ 8 <1 17 17 17 17 17 17 17 17 17 17 17 17>,
					/bits/ 8 <1 22 22 22 22 22 22 22 22 22 22 22 22>,
					/bits/ 8 <1 27 27 27 27 27 27 27 27 27 27 27 27>;
					paths-ofdm = /bits/ 8 <11 11 11 11>;
					paths-ofdm-bf = /bits/ 8 <0 11 11 11>;
					paths-ru =
					/bits/ 8 <4 11 11 11 11 11 11 11 11 11 11>,
					/bits/ 8 <1 17 17 17 17 17 17 17 17 17 17>,
					/bits/ 8 <1 22 22 22 22 22 22 22 22 22 22>,
					/bits/ 8 <1 27 27 27 27 27 27 27 27 27 27>;
					paths-ru-bf =
					/bits/ 8 <3 10 10 10 10 10 10 10 10 10 10>,
					/bits/ 8 <1 0 10 10 10 10 10 10 10 10 10>,
					/bits/ 8 <1 0 16 16 16 16 16 16 16 16 16>,
					/bits/ 8 <1 0 22 22 22 22 22 22 22 22 22>,
					/bits/ 8 <1 0 27 27 27 27 27 27 27 27 27>;
				};
				r1 {
					channels = <33 37>;
					txs-delta = <0 0 0>;
					rates-cck = /bits/ 8 <63 63 63 63>;
					rates-ofdm = /bits/ 8 <9 9 9 9 9 9 9 9>;
					rates-mcs =
					/bits/ 8 <1 11 11 11 11 11 11 11 11 11 11>,
					/bits/ 8 <1 17 17 17 17 17 17 17 17 17 17>,
					/bits/ 8 <1 22 22 22 22 22 22 22 22 22 22>,
					/bits/ 8 <1 28 28 28 28 28 28 28 28 28 28>;
					rates-ru =
					/bits/ 8 <4 11 11 11 11 11 11 11 11 11 11 11 11>,
					/bits/ 8 <1 17 17 17 17 17 17 17 17 17 17 17 17>,
					/bits/ 8 <1 22 22 22 22 22 22 22 22 22 22 22 22>,
					/bits/ 8 <1 28 28 28 28 28 28 28 28 28 28 28 28>;
					paths-ofdm = /bits/ 8 <11 11 11 11>;
					paths-ofdm-bf = /bits/ 8 <0 11 11 11>;
					paths-ru =
					/bits/ 8 <4 11 11 11 11 11 11 11 11 11 11>,
					/bits/ 8 <1 17 17 17 17 17 17 17 17 17 17>,
					/bits/ 8 <1 22 22 22 22 22 22 22 22 22 22>,
					/bits/ 8 <1 28 28 28 28 28 28 28 28 28 28>;
					paths-ru-bf =
					/bits/ 8 <3 10 10 10 10 10 10 10 10 10 10>,
					/bits/ 8 <1 0 10 10 10 10 10 10 10 10 10>,
					/bits/ 8 <1 0 16 16 16 16 16 16 16 16 16>,
					/bits/ 8 <1 0 22 22 22 22 22 22 22 22 22>,
					/bits/ 8 <1 0 27 27 27 27 27 27 27 27 27>;
				};
				r2 {
					channels = <41 45>;
					txs-delta = <0 0 0>;
					rates-cck = /bits/ 8 <63 63 63 63>;
					rates-ofdm = /bits/ 8 <9 9 9 9 9 9 9 9>;
					rates-mcs =
					/bits/ 8 <1 11 11 11 11 11 11 11 11 11 11>,
					/bits/ 8 <1 16 16 16 16 16 16 16 16 16 16>,
					/bits/ 8 <1 22 22 22 22 22 22 22 22 22 22>,
					/bits/ 8 <1 28 28 28 28 28 28 28 28 28 28>;
					rates-ru =
					/bits/ 8 <4 11 11 11 11 11 11 11 11 11 11 11 11>,
					/bits/ 8 <1 16 16 16 16 16 16 16 16 16 16 16 16>,
					/bits/ 8 <1 22 22 22 22 22 22 22 22 22 22 22 22>,
					/bits/ 8 <1 28 28 28 28 28 28 28 28 28 28 28 28>;
					paths-ofdm = /bits/ 8 <11 11 11 11>;
					paths-ofdm-bf = /bits/ 8 <0 11 11 11>;
					paths-ru =
					/bits/ 8 <4 11 11 11 11 11 11 11 11 11 11>,
					/bits/ 8 <1 16 16 16 16 16 16 16 16 16 16>,
					/bits/ 8 <1 22 22 22 22 22 22 22 22 22 22>,
					/bits/ 8 <1 28 28 28 28 28 28 28 28 28 28>;
					paths-ru-bf =
					/bits/ 8 <3 10 10 10 10 10 10 10 10 10 10>,
					/bits/ 8 <1 0 10 10 10 10 10 10 10 10 10>,
					/bits/ 8 <1 0 16 16 16 16 16 16 16 16 16>,
					/bits/ 8 <1 0 22 22 22 22 22 22 22 22 22>,
					/bits/ 8 <1 0 27 27 27 27 27 27 27 27 27>;
				};
				r3 {
					channels = <49 61>;
					txs-delta = <0 0 0>;
					rates-cck = /bits/ 8 <63 63 63 63>;
					rates-ofdm = /bits/ 8 <9 9 9 9 9 9 9 9>;
					rates-mcs =
					/bits/ 8 <1 11 11 11 11 11 11 11 11 11 11>,
					/bits/ 8 <1 16 16 16 16 16 16 16 16 16 16>,
					/bits/ 8 <1 23 23 23 23 23 23 23 23 23 23>,
					/bits/ 8 <1 28 28 28 28 28 28 28 28 28 28>;
					rates-ru =
					/bits/ 8 <4 11 11 11 11 11 11 11 11 11 11 11 11>,
					/bits/ 8 <1 16 16 16 16 16 16 16 16 16 16 16 16>,
					/bits/ 8 <1 23 23 23 23 23 23 23 23 23 23 23 23>,
					/bits/ 8 <1 28 28 28 28 28 28 28 28 28 28 28 28>;
					paths-ofdm = /bits/ 8 <11 11 11 11>;
					paths-ofdm-bf = /bits/ 8 <0 11 11 11>;
					paths-ru =
					/bits/ 8 <4 11 11 11 11 11 11 11 11 11 11>,
					/bits/ 8 <1 16 16 16 16 16 16 16 16 16 16>,
					/bits/ 8 <1 23 23 23 23 23 23 23 23 23 23>,
					/bits/ 8 <1 28 28 28 28 28 28 28 28 28 28>;
					paths-ru-bf =
					/bits/ 8 <3 10 10 10 10 10 10 10 10 10 10>,
					/bits/ 8 <1 0 10 10 10 10 10 10 10 10 10>,
					/bits/ 8 <1 0 16 16 16 16 16 16 16 16 16>,
					/bits/ 8 <1 0 22 22 22 22 22 22 22 22 22>,
					/bits/ 8 <1 0 27 27 27 27 27 27 27 27 27>;
				};
				r4 {
					channels = <65 89>;
					txs-delta = <0 0 0>;
					rates-cck = /bits/ 8 <63 63 63 63>;
					rates-ofdm = /bits/ 8 <9 9 9 9 9 9 9 9>;
					rates-mcs =
					/bits/ 8 <1 11 11 11 11 11 11 11 11 11 11>,
					/bits/ 8 <1 16 16 16 16 16 16 16 16 16 16>,
					/bits/ 8 <1 23 23 23 23 23 23 23 23 23 23>,
					/bits/ 8 <1 27 27 27 27 27 27 27 27 27 27>;
					rates-ru =
					/bits/ 8 <4 11 11 11 11 11 11 11 11 11 11 11 11>,
					/bits/ 8 <1 16 16 16 16 16 16 16 16 16 16 16 16>,
					/bits/ 8 <1 23 23 23 23 23 23 23 23 23 23 23 23>,
					/bits/ 8 <1 27 27 27 27 27 27 27 27 27 27 27 27>;
					paths-ofdm = /bits/ 8 <11 11 11 11>;
					paths-ofdm-bf = /bits/ 8 <0 11 11 11>;
					paths-ru =
					/bits/ 8 <4 11 11 11 11 11 11 11 11 11 11>,
					/bits/ 8 <1 16 16 16 16 16 16 16 16 16 16>,
					/bits/ 8 <1 23 23 23 23 23 23 23 23 23 23>,
					/bits/ 8 <1 27 27 27 27 27 27 27 27 27 27>;
					paths-ru-bf =
					/bits/ 8 <3 10 10 10 10 10 10 10 10 10 10>,
					/bits/ 8 <1 0 10 10 10 10 10 10 10 10 10>,
					/bits/ 8 <1 0 16 16 16 16 16 16 16 16 16>,
					/bits/ 8 <1 0 22 22 22 22 22 22 22 22 22>,
					/bits/ 8 <1 0 27 27 27 27 27 27 27 27 27>;
				};
				r5 {
					channels = <93 93>;
					txs-delta = <0 0 0>;
					rates-cck = /bits/ 8 <63 63 63 63>;
					rates-ofdm = /bits/ 8 <9 9 9 9 9 9 9 9>;
					rates-mcs =
					/bits/ 8 <1 11 11 11 11 11 11 11 11 11 11>,
					/bits/ 8 <1 16 16 16 16 16 16 16 16 16 16>,
					/bits/ 8 <1 23 23 23 23 23 23 23 23 23 23>,
					/bits/ 8 <1 27 27 27 27 27 27 27 27 27 27>;
					rates-ru =
					/bits/ 8 <4 11 11 11 11 11 11 11 11 11 11 11 11>,
					/bits/ 8 <1 16 16 16 16 16 16 16 16 16 16 16 16>,
					/bits/ 8 <1 23 23 23 23 23 23 23 23 23 23 23 23>,
					/bits/ 8 <1 27 27 27 27 27 27 27 27 27 27 27 27>;
					paths-ofdm = /bits/ 8 <11 11 11 11>;
					paths-ofdm-bf = /bits/ 8 <0 11 11 11>;
					paths-ru =
					/bits/ 8 <4 11 11 11 11 11 11 11 11 11 11>,
					/bits/ 8 <1 16 16 16 16 16 16 16 16 16 16>,
					/bits/ 8 <1 23 23 23 23 23 23 23 23 23 23>,
					/bits/ 8 <1 27 27 27 27 27 27 27 27 27 27>;
					paths-ru-bf =
					/bits/ 8 <3 11 11 11 11 11 11 11 11 11 11>,
					/bits/ 8 <1 0 11 11 11 11 11 11 11 11 11>,
					/bits/ 8 <1 0 16 16 16 16 16 16 16 16 16>,
					/bits/ 8 <1 0 22 22 22 22 22 22 22 22 22>,
					/bits/ 8 <1 0 27 27 27 27 27 27 27 27 27>;
				};
				r6 {
					channels = <97 101>;
					txs-delta = <0 0 0>;
					rates-cck = /bits/ 8 <63 63 63 63>;
					rates-ofdm = /bits/ 8 <9 9 9 9 9 9 9 9>;
					rates-mcs =
					/bits/ 8 <1 12 12 12 12 12 12 12 12 12 12>,
					/bits/ 8 <1 17 17 17 17 17 17 17 17 17 17>,
					/bits/ 8 <1 24 24 24 24 24 24 24 24 24 24>,
					/bits/ 8 <1 27 27 27 27 27 27 27 27 27 27>;
					rates-ru =
					/bits/ 8 <4 12 12 12 12 12 12 12 12 12 12 12 12>,
					/bits/ 8 <1 17 17 17 17 17 17 17 17 17 17 17 17>,
					/bits/ 8 <1 24 24 24 24 24 24 24 24 24 24 24 24>,
					/bits/ 8 <1 27 27 27 27 27 27 27 27 27 27 27 27>;
					paths-ofdm = /bits/ 8 <12 12 12 12>;
					paths-ofdm-bf = /bits/ 8 <0 12 12 12>;
					paths-ru =
					/bits/ 8 <4 12 12 12 12 12 12 12 12 12 12>,
					/bits/ 8 <1 17 17 17 17 17 17 17 17 17 17>,
					/bits/ 8 <1 24 24 24 24 24 24 24 24 24 24>,
					/bits/ 8 <1 27 27 27 27 27 27 27 27 27 27>;
					paths-ru-bf =
					/bits/ 8 <3 11 11 11 11 11 11 11 11 11 11>,
					/bits/ 8 <1 0 11 11 11 11 11 11 11 11 11>,
					/bits/ 8 <1 0 16 16 16 16 16 16 16 16 16>,
					/bits/ 8 <1 0 23 23 23 23 23 23 23 23 23>,
					/bits/ 8 <1 0 27 27 27 27 27 27 27 27 27>;
				};
				r7 {
					channels = <105 109>;
					txs-delta = <0 0 0>;
					rates-cck = /bits/ 8 <63 63 63 63>;
					rates-ofdm = /bits/ 8 <9 9 9 9 9 9 9 9>;
					rates-mcs =
					/bits/ 8 <1 11 11 11 11 11 11 11 11 11 11>,
					/bits/ 8 <1 16 16 16 16 16 16 16 16 16 16>,
					/bits/ 8 <1 24 24 24 24 24 24 24 24 24 24>,
					/bits/ 8 <1 27 27 27 27 27 27 27 27 27 27>;
					rates-ru =
					/bits/ 8 <4 11 11 11 11 11 11 11 11 11 11 11 11>,
					/bits/ 8 <1 16 16 16 16 16 16 16 16 16 16 16 16>,
					/bits/ 8 <1 24 24 24 24 24 24 24 24 24 24 24 24>,
					/bits/ 8 <1 27 27 27 27 27 27 27 27 27 27 27 27>;
					paths-ofdm = /bits/ 8 <11 11 11 11>;
					paths-ofdm-bf = /bits/ 8 <0 11 11 11>;
					paths-ru =
					/bits/ 8 <4 11 11 11 11 11 11 11 11 11 11>,
					/bits/ 8 <1 16 16 16 16 16 16 16 16 16 16>,
					/bits/ 8 <1 24 24 24 24 24 24 24 24 24 24>,
					/bits/ 8 <1 27 27 27 27 27 27 27 27 27 27>;
					paths-ru-bf =
					/bits/ 8 <3 11 11 11 11 11 11 11 11 11 11>,
					/bits/ 8 <1 0 11 11 11 11 11 11 11 11 11>,
					/bits/ 8 <1 0 16 16 16 16 16 16 16 16 16>,
					/bits/ 8 <1 0 23 23 23 23 23 23 23 23 23>,
					/bits/ 8 <1 0 27 27 27 27 27 27 27 27 27>;
				};
				r8 {
					channels = <113 113>;
					txs-delta = <0 0 0>;
					rates-cck = /bits/ 8 <63 63 63 63>;
					rates-ofdm = /bits/ 8 <10 10 10 10 10 10 10 10>;
					rates-mcs =
					/bits/ 8 <1 11 11 11 11 11 11 11 11 11 11>,
					/bits/ 8 <1 16 16 16 16 16 16 16 16 16 16>,
					/bits/ 8 <1 22 22 22 22 22 22 22 22 22 22>,
					/bits/ 8 <1 27 27 27 27 27 27 27 27 27 27>;
					rates-ru =
					/bits/ 8 <4 11 11 11 11 11 11 11 11 11 11 11 11>,
					/bits/ 8 <1 16 16 16 16 16 16 16 16 16 16 16 16>,
					/bits/ 8 <1 22 22 22 22 22 22 22 22 22 22 22 22>,
					/bits/ 8 <1 27 27 27 27 27 27 27 27 27 27 27 27>;
					paths-ofdm = /bits/ 8 <11 11 11 11>;
					paths-ofdm-bf = /bits/ 8 <0 11 11 11>;
					paths-ru =
					/bits/ 8 <4 11 11 11 11 11 11 11 11 11 11>,
					/bits/ 8 <1 16 16 16 16 16 16 16 16 16 16>,
					/bits/ 8 <1 22 22 22 22 22 22 22 22 22 22>,
					/bits/ 8 <1 27 27 27 27 27 27 27 27 27 27>;
					paths-ru-bf =
					/bits/ 8 <3 11 11 11 11 11 11 11 11 11 11>,
					/bits/ 8 <1 0 11 11 11 11 11 11 11 11 11>,
					/bits/ 8 <1 0 16 16 16 16 16 16 16 16 16>,
					/bits/ 8 <1 0 22 22 22 22 22 22 22 22 22>,
					/bits/ 8 <1 0 27 27 27 27 27 27 27 27 27>;
				};
				r9 {
					channels = <117 125>;
					txs-delta = <0 0 0>;
					rates-cck = /bits/ 8 <63 63 63 63>;
					rates-ofdm = /bits/ 8 <10 10 10 10 10 10 10 10>;
					rates-mcs =
					/bits/ 8 <1 10 10 10 10 10 10 10 10 10 10>,
					/bits/ 8 <1 16 16 16 16 16 16 16 16 16 16>,
					/bits/ 8 <1 22 22 22 22 22 22 22 22 22 22>,
					/bits/ 8 <1 27 27 27 27 27 27 27 27 27 27>;
					rates-ru =
					/bits/ 8 <4 10 10 10 10 10 10 10 10 10 10 10 10>,
					/bits/ 8 <1 16 16 16 16 16 16 16 16 16 16 16 16>,
					/bits/ 8 <1 22 22 22 22 22 22 22 22 22 22 22 22>,
					/bits/ 8 <1 27 27 27 27 27 27 27 27 27 27 27 27>;
					paths-ofdm = /bits/ 8 <10 10 10 10>;
					paths-ofdm-bf = /bits/ 8 <0 10 10 10>;
					paths-ru =
					/bits/ 8 <4 10 10 10 10 10 10 10 10 10 10>,
					/bits/ 8 <1 16 16 16 16 16 16 16 16 16 16>,
					/bits/ 8 <1 22 22 22 22 22 22 22 22 22 22>,
					/bits/ 8 <1 27 27 27 27 27 27 27 27 27 27>;
					paths-ru-bf =
					/bits/ 8 <3 10 10 10 10 10 10 10 10 10 10>,
					/bits/ 8 <1 0 10 10 10 10 10 10 10 10 10>,
					/bits/ 8 <1 0 16 16 16 16 16 16 16 16 16>,
					/bits/ 8 <1 0 22 22 22 22 22 22 22 22 22>,
					/bits/ 8 <1 0 27 27 27 27 27 27 27 27 27>;
				};
				r10 {
					channels = <129 153>;
					txs-delta = <0 0 0>;
					rates-cck = /bits/ 8 <63 63 63 63>;
					rates-ofdm = /bits/ 8 <10 10 10 10 10 10 10 10>;
					rates-mcs =
					/bits/ 8 <1 10 10 10 10 10 10 10 10 10 10>,
					/bits/ 8 <1 16 16 16 16 16 16 16 16 16 16>,
					/bits/ 8 <1 22 22 22 22 22 22 22 22 22 22>,
					/bits/ 8 <1 28 28 28 28 28 28 28 28 28 28>;
					rates-ru =
					/bits/ 8 <4 10 10 10 10 10 10 10 10 10 10 10 10>,
					/bits/ 8 <1 16 16 16 16 16 16 16 16 16 16 16 16>,
					/bits/ 8 <1 22 22 22 22 22 22 22 22 22 22 22 22>,
					/bits/ 8 <1 28 28 28 28 28 28 28 28 28 28 28 28>;
					paths-ofdm = /bits/ 8 <10 10 10 10>;
					paths-ofdm-bf = /bits/ 8 <0 10 10 10>;
					paths-ru =
					/bits/ 8 <4 10 10 10 10 10 10 10 10 10 10>,
					/bits/ 8 <1 16 16 16 16 16 16 16 16 16 16>,
					/bits/ 8 <1 22 22 22 22 22 22 22 22 22 22>,
					/bits/ 8 <1 28 28 28 28 28 28 28 28 28 28>;
					paths-ru-bf =
					/bits/ 8 <3 10 10 10 10 10 10 10 10 10 10>,
					/bits/ 8 <1 0 10 10 10 10 10 10 10 10 10>,
					/bits/ 8 <1 0 16 16 16 16 16 16 16 16 16>,
					/bits/ 8 <1 0 22 22 22 22 22 22 22 22 22>,
					/bits/ 8 <1 0 27 27 27 27 27 27 27 27 27>;
				};
				r11 {
					channels = <157 157>;
					txs-delta = <0 0 0>;
					rates-cck = /bits/ 8 <63 63 63 63>;
					rates-ofdm = /bits/ 8 <10 10 10 10 10 10 10 10>;
					rates-mcs =
					/bits/ 8 <1 11 11 11 11 11 11 11 11 11 11>,
					/bits/ 8 <1 16 16 16 16 16 16 16 16 16 16>,
					/bits/ 8 <1 22 22 22 22 22 22 22 22 22 22>,
					/bits/ 8 <1 28 28 28 28 28 28 28 28 28 28>;
					rates-ru =
					/bits/ 8 <4 11 11 11 11 11 11 11 11 11 11 11 11>,
					/bits/ 8 <1 16 16 16 16 16 16 16 16 16 16 16 16>,
					/bits/ 8 <1 22 22 22 22 22 22 22 22 22 22 22 22>,
					/bits/ 8 <1 28 28 28 28 28 28 28 28 28 28 28 28>;
					paths-ofdm = /bits/ 8 <11 11 11 11>;
					paths-ofdm-bf = /bits/ 8 <0 11 11 11>;
					paths-ru =
					/bits/ 8 <4 11 11 11 11 11 11 11 11 11 11>,
					/bits/ 8 <1 16 16 16 16 16 16 16 16 16 16>,
					/bits/ 8 <1 22 22 22 22 22 22 22 22 22 22>,
					/bits/ 8 <1 28 28 28 28 28 28 28 28 28 28>;
					paths-ru-bf =
					/bits/ 8 <3 10 10 10 10 10 10 10 10 10 10>,
					/bits/ 8 <1 0 10 10 10 10 10 10 10 10 10>,
					/bits/ 8 <1 0 16 16 16 16 16 16 16 16 16>,
					/bits/ 8 <1 0 22 22 22 22 22 22 22 22 22>,
					/bits/ 8 <1 0 27 27 27 27 27 27 27 27 27>;
				};
				r12 {
					channels = <161 177>;
					txs-delta = <0 0 0>;
					rates-cck = /bits/ 8 <63 63 63 63>;
					rates-ofdm = /bits/ 8 <10 10 10 10 10 10 10 10>;
					rates-mcs =
					/bits/ 8 <1 11 11 11 11 11 11 11 11 11 11>,
					/bits/ 8 <1 16 16 16 16 16 16 16 16 16 16>,
					/bits/ 8 <1 23 23 23 23 23 23 23 23 23 23>,
					/bits/ 8 <1 27 27 27 27 27 27 27 27 27 27>;
					rates-ru =
					/bits/ 8 <4 11 11 11 11 11 11 11 11 11 11 11 11>,
					/bits/ 8 <1 16 16 16 16 16 16 16 16 16 16 16 16>,
					/bits/ 8 <1 23 23 23 23 23 23 23 23 23 23 23 23>,
					/bits/ 8 <1 27 27 27 27 27 27 27 27 27 27 27 27>;
					paths-ofdm = /bits/ 8 <11 11 11 11>;
					paths-ofdm-bf = /bits/ 8 <0 11 11 11>;
					paths-ru =
					/bits/ 8 <4 11 11 11 11 11 11 11 11 11 11>,
					/bits/ 8 <1 16 16 16 16 16 16 16 16 16 16>,
					/bits/ 8 <1 23 23 23 23 23 23 23 23 23 23>,
					/bits/ 8 <1 27 27 27 27 27 27 27 27 27 27>;
					paths-ru-bf =
					/bits/ 8 <3 10 10 10 10 10 10 10 10 10 10>,
					/bits/ 8 <1 0 10 10 10 10 10 10 10 10 10>,
					/bits/ 8 <1 0 16 16 16 16 16 16 16 16 16>,
					/bits/ 8 <1 0 22 22 22 22 22 22 22 22 22>,
					/bits/ 8 <1 0 27 27 27 27 27 27 27 27 27>;
				};
				r13 {
					channels = <181 181>;
					txs-delta = <0 0 0>;
					rates-cck = /bits/ 8 <63 63 63 63>;
					rates-ofdm = /bits/ 8 <9 9 9 9 9 9 9 9>;
					rates-mcs =
					/bits/ 8 <1 11 11 11 11 11 11 11 11 11 11>,
					/bits/ 8 <1 16 16 16 16 16 16 16 16 16 16>,
					/bits/ 8 <1 23 23 23 23 23 23 23 23 23 23>,
					/bits/ 8 <1 27 27 27 27 27 27 27 27 27 27>;
					rates-ru =
					/bits/ 8 <4 11 11 11 11 11 11 11 11 11 11 11 11>,
					/bits/ 8 <1 16 16 16 16 16 16 16 16 16 16 16 16>,
					/bits/ 8 <1 23 23 23 23 23 23 23 23 23 23 23 23>,
					/bits/ 8 <1 27 27 27 27 27 27 27 27 27 27 27 27>;
					paths-ofdm = /bits/ 8 <11 11 11 11>;
					paths-ofdm-bf = /bits/ 8 <0 11 11 11>;
					paths-ru =
					/bits/ 8 <4 11 11 11 11 11 11 11 11 11 11>,
					/bits/ 8 <1 16 16 16 16 16 16 16 16 16 16>,
					/bits/ 8 <1 23 23 23 23 23 23 23 23 23 23>,
					/bits/ 8 <1 27 27 27 27 27 27 27 27 27 27>;
					paths-ru-bf =
					/bits/ 8 <3 10 10 10 10 10 10 10 10 10 10>,
					/bits/ 8 <1 0 10 10 10 10 10 10 10 10 10>,
					/bits/ 8 <1 0 16 16 16 16 16 16 16 16 16>,
					/bits/ 8 <1 0 22 22 22 22 22 22 22 22 22>,
					/bits/ 8 <1 0 27 27 27 27 27 27 27 27 27>;
				};
				r14 {
					channels = <185 185>;
					txs-delta = <0 0 0>;
					rates-cck = /bits/ 8 <63 63 63 63>;
					rates-ofdm = /bits/ 8 <9 9 9 9 9 9 9 9>;
					rates-mcs =
					/bits/ 8 <1 11 11 11 11 11 11 11 11 11 11>,
					/bits/ 8 <1 16 16 16 16 16 16 16 16 16 16>,
					/bits/ 8 <1 23 23 23 23 23 23 23 23 23 23>,
					/bits/ 8 <1 27 27 27 27 27 27 27 27 27 27>;
					rates-ru =
					/bits/ 8 <4 11 11 11 11 11 11 11 11 11 11 11 11>,
					/bits/ 8 <1 16 16 16 16 16 16 16 16 16 16 16 16>,
					/bits/ 8 <1 23 23 23 23 23 23 23 23 23 23 23 23>,
					/bits/ 8 <1 27 27 27 27 27 27 27 27 27 27 27 27>;
					paths-ofdm = /bits/ 8 <11 11 11 11>;
					paths-ofdm-bf = /bits/ 8 <0 11 11 11>;
					paths-ru =
					/bits/ 8 <4 11 11 11 11 11 11 11 11 11 11>,
					/bits/ 8 <1 16 16 16 16 16 16 16 16 16 16>,
					/bits/ 8 <1 23 23 23 23 23 23 23 23 23 23>,
					/bits/ 8 <1 27 27 27 27 27 27 27 27 27 27>;
					paths-ru-bf =
					/bits/ 8 <3 11 11 11 11 11 11 11 11 11 11>,
					/bits/ 8 <1 0 11 11 11 11 11 11 11 11 11>,
					/bits/ 8 <1 0 15 15 15 15 15 15 15 15 15>,
					/bits/ 8 <1 0 22 22 22 22 22 22 22 22 22>,
					/bits/ 8 <1 0 27 27 27 27 27 27 27 27 27>;
				};
				r15 {
					channels = <189 189>;
					txs-delta = <0 0 0>;
					rates-cck = /bits/ 8 <63 63 63 63>;
					rates-ofdm = /bits/ 8 <12 12 12 12 12 12 12 12>;
					rates-mcs =
					/bits/ 8 <1 13 13 13 13 13 13 13 13 13 13>,
					/bits/ 8 <1 16 16 16 16 16 16 16 16 16 16>,
					/bits/ 8 <1 23 23 23 23 23 23 23 23 23 23>,
					/bits/ 8 <1 27 27 27 27 27 27 27 27 27 27>;
					rates-ru =
					/bits/ 8 <4 13 13 13 13 13 13 13 13 13 13 13 13>,
					/bits/ 8 <1 16 16 16 16 16 16 16 16 16 16 16 16>,
					/bits/ 8 <1 23 23 23 23 23 23 23 23 23 23 23 23>,
					/bits/ 8 <1 27 27 27 27 27 27 27 27 27 27 27 27>;
					paths-ofdm = /bits/ 8 <13 13 13 13>;
					paths-ofdm-bf = /bits/ 8 <0 13 13 13>;
					paths-ru =
					/bits/ 8 <4 13 13 13 13 13 13 13 13 13 13>,
					/bits/ 8 <1 16 16 16 16 16 16 16 16 16 16>,
					/bits/ 8 <1 23 23 23 23 23 23 23 23 23 23>,
					/bits/ 8 <1 27 27 27 27 27 27 27 27 27 27>;
					paths-ru-bf =
					/bits/ 8 <3 13 13 13 13 13 13 13 13 13 13>,
					/bits/ 8 <1 0 13 13 13 13 13 13 13 13 13>,
					/bits/ 8 <1 0 15 15 15 15 15 15 15 15 15>,
					/bits/ 8 <1 0 22 22 22 22 22 22 22 22 22>,
					/bits/ 8 <1 0 27 27 27 27 27 27 27 27 27>;
				};
				r16 {
					channels = <193 221>;
					txs-delta = <0 0 0>;
					rates-cck = /bits/ 8 <63 63 63 63>;
					rates-ofdm = /bits/ 8 <12 12 12 12 12 12 12 12>;
					rates-mcs =
					/bits/ 8 <1 13 13 13 13 13 13 13 13 13 13>,
					/bits/ 8 <1 18 18 18 18 18 18 18 18 18 18>,
					/bits/ 8 <1 25 25 25 25 25 25 25 25 25 25>,
					/bits/ 8 <1 30 30 30 30 30 30 30 30 30 30>;
					rates-ru =
					/bits/ 8 <4 13 13 13 13 13 13 13 13 13 13 13 13>,
					/bits/ 8 <1 18 18 18 18 18 18 18 18 18 18 18 18>,
					/bits/ 8 <1 25 25 25 25 25 25 25 25 25 25 25 25>,
					/bits/ 8 <1 30 30 30 30 30 30 30 30 30 30 30 30>;
					paths-ofdm = /bits/ 8 <13 13 13 13>;
					paths-ofdm-bf = /bits/ 8 <0 13 13 13>;
					paths-ru =
					/bits/ 8 <4 13 13 13 13 13 13 13 13 13 13>,
					/bits/ 8 <1 18 18 18 18 18 18 18 18 18 18>,
					/bits/ 8 <1 25 25 25 25 25 25 25 25 25 25>,
					/bits/ 8 <1 30 30 30 30 30 30 30 30 30 30>;
					paths-ru-bf =
					/bits/ 8 <3 13 13 13 13 13 13 13 13 13 13>,
					/bits/ 8 <1 0 13 13 13 13 13 13 13 13 13>,
					/bits/ 8 <1 0 18 18 18 18 18 18 18 18 18>,
					/bits/ 8 <1 0 24 24 24 24 24 24 24 24 24>,
					/bits/ 8 <1 0 30 30 30 30 30 30 30 30 30>;
				};
				r17 {
					channels = <225 225>;
					txs-delta = <0 0 0>;
					rates-cck = /bits/ 8 <63 63 63 63>;
					rates-ofdm = /bits/ 8 <12 12 12 12 12 12 12 12>;
					rates-mcs =
					/bits/ 8 <1 13 13 13 13 13 13 13 13 13 13>,
					/bits/ 8 <1 18 18 18 18 18 18 18 18 18 18>,
					/bits/ 8 <1 22 22 22 22 22 22 22 22 22 22>,
					/bits/ 8 <1 27 27 27 27 27 27 27 27 27 27>;
					rates-ru =
					/bits/ 8 <4 13 13 13 13 13 13 13 13 13 13 13 13>,
					/bits/ 8 <1 18 18 18 18 18 18 18 18 18 18 18 18>,
					/bits/ 8 <1 22 22 22 22 22 22 22 22 22 22 22 22>,
					/bits/ 8 <1 27 27 27 27 27 27 27 27 27 27 27 27>;
					paths-ofdm = /bits/ 8 <13 13 13 13>;
					paths-ofdm-bf = /bits/ 8 <0 13 13 13>;
					paths-ru =
					/bits/ 8 <4 13 13 13 13 13 13 13 13 13 13>,
					/bits/ 8 <1 18 18 18 18 18 18 18 18 18 18>,
					/bits/ 8 <1 22 22 22 22 22 22 22 22 22 22>,
					/bits/ 8 <1 27 27 27 27 27 27 27 27 27 27>;
					paths-ru-bf =
					/bits/ 8 <3 13 13 13 13 13 13 13 13 13 13>,
					/bits/ 8 <1 0 13 13 13 13 13 13 13 13 13>,
					/bits/ 8 <1 0 18 18 18 18 18 18 18 18 18>,
					/bits/ 8 <1 0 22 22 22 22 22 22 22 22 22>,
					/bits/ 8 <1 0 27 27 27 27 27 27 27 27 27>;
				};
				r18 {
					channels = <229 229>;
					txs-delta = <0 0 0>;
					rates-cck = /bits/ 8 <63 63 63 63>;
					rates-ofdm = /bits/ 8 <12 12 12 12 12 12 12 12>;
					rates-mcs =
					/bits/ 8 <1 13 13 13 13 13 13 13 13 13 13>,
					/bits/ 8 <1 18 18 18 18 18 18 18 18 18 18>,
					/bits/ 8 <1 22 22 22 22 22 22 22 22 22 22>,
					/bits/ 8 <1 27 27 27 27 27 27 27 27 27 27>;
					rates-ru =
					/bits/ 8 <4 13 13 13 13 13 13 13 13 13 13 13 13>,
					/bits/ 8 <1 18 18 18 18 18 18 18 18 18 18 18 18>,
					/bits/ 8 <1 22 22 22 22 22 22 22 22 22 22 22 22>,
					/bits/ 8 <1 27 27 27 27 27 27 27 27 27 27 27 27>;
					paths-ofdm = /bits/ 8 <13 13 13 13>;
					paths-ofdm-bf = /bits/ 8 <0 13 13 13>;
					paths-ru =
					/bits/ 8 <4 13 13 13 13 13 13 13 13 13 13>,
					/bits/ 8 <1 18 18 18 18 18 18 18 18 18 18>,
					/bits/ 8 <1 22 22 22 22 22 22 22 22 22 22>,
					/bits/ 8 <1 27 27 27 27 27 27 27 27 27 27>;
					paths-ru-bf =
					/bits/ 8 <3 12 12 12 12 12 12 12 12 12 12>,
					/bits/ 8 <1 0 12 12 12 12 12 12 12 12 12>,
					/bits/ 8 <1 0 18 18 18 18 18 18 18 18 18>,
					/bits/ 8 <1 0 22 22 22 22 22 22 22 22 22>,
					/bits/ 8 <1 0 27 27 27 27 27 27 27 27 27>;
				};
				r19 {
					channels = <233 233>;
					txs-delta = <0 0 0>;
					rates-cck = /bits/ 8 <63 63 63 63>;
					rates-ofdm = /bits/ 8 <10 10 10 10 10 10 10 10>;
					rates-mcs =
					/bits/ 8 <1 9 9 9 9 9 9 9 9 9 9>,
					/bits/ 8 <1 16 16 16 16 16 16 16 16 16 16>,
					/bits/ 8 <1 22 22 22 22 22 22 22 22 22 22>,
					/bits/ 8 <1 27 27 27 27 27 27 27 27 27 27>;
					rates-ru =
					/bits/ 8 <4 9 9 9 9 9 9 9 9 9 9 9 9>,
					/bits/ 8 <1 16 16 16 16 16 16 16 16 16 16 16 16>,
					/bits/ 8 <1 22 22 22 22 22 22 22 22 22 22 22 22>,
					/bits/ 8 <1 27 27 27 27 27 27 27 27 27 27 27 27>;
					paths-ofdm = /bits/ 8 <9 9 9 9>;
					paths-ofdm-bf = /bits/ 8 <0 9 9 9>;
					paths-ru =
					/bits/ 8 <4 9 9 9 9 9 9 9 9 9 9>,
					/bits/ 8 <1 36 36 36 36 36 36 36 36 36 36>,
					/bits/ 8 <1 22 22 22 22 22 22 22 22 22 22>,
					/bits/ 8 <1 27 27 27 27 27 27 27 27 27 27>;
					paths-ru-bf =
					/bits/ 8 <3 9 9 9 9 9 9 9 9 9 9>,
					/bits/ 8 <1 0 9 9 9 9 9 9 9 9 9>,
					/bits/ 8 <1 0 22 30 28 36 24 26 30 32 34>,
					/bits/ 8 <1 0 22 22 22 22 22 22 22 22 22>,
					/bits/ 8 <1 0 27 27 27 27 27 27 27 27 27>;
				};
			};
		};
	};
};
